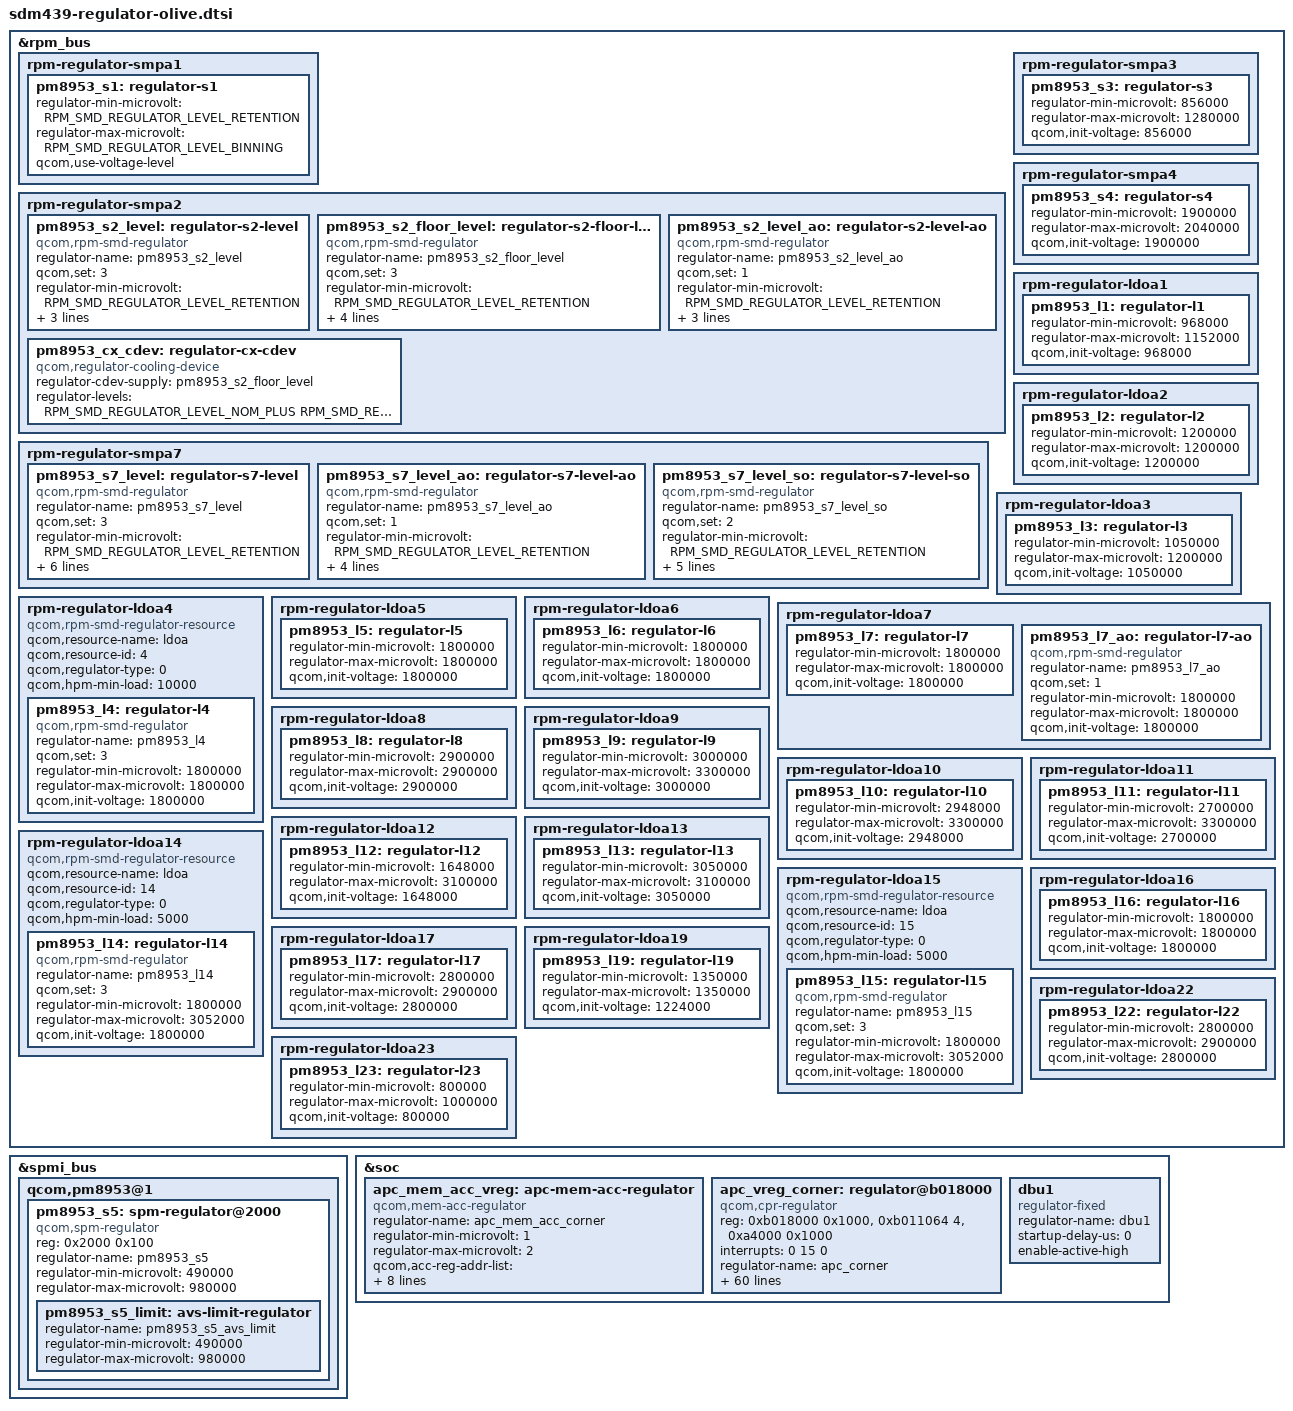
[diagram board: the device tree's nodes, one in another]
/*
 * Copyright (c) 2018-2019, The Linux Foundation. All rights reserved.
 * Copyright (C) 2021 XiaoMi, Inc.
 *
 * This program is free software; you can redistribute it and/or modify
 * it under the terms of the GNU General Public License version 2 and
 * only version 2 as published by the Free Software Foundation.
 *
 * This program is distributed in the hope that it will be useful,
 * but WITHOUT ANY WARRANTY; without even the implied warranty of
 * MERCHANTABILITY or FITNESS FOR A PARTICULAR PURPOSE.  See the
 * GNU General Public License for more details.
 */

#include <dt-bindings/interrupt-controller/arm-gic.h>

&rpm_bus {
	/* PM8953 regulators */
	rpm-regulator-smpa1 {
		status = "okay";
		pm8953_s1: regulator-s1 {
			regulator-min-microvolt =
					<RPM_SMD_REGULATOR_LEVEL_RETENTION>;
			regulator-max-microvolt =
					<RPM_SMD_REGULATOR_LEVEL_BINNING>;
			qcom,use-voltage-level;
			status = "okay";
		};
	};

	/* PM8953 S2 - VDD_CX supply */
	rpm-regulator-smpa2 {
		status = "okay";
		pm8953_s2_level: regulator-s2-level {
			compatible = "qcom,rpm-smd-regulator";
			regulator-name = "pm8953_s2_level";
			qcom,set = <3>;
			regulator-min-microvolt =
					<RPM_SMD_REGULATOR_LEVEL_RETENTION>;
			regulator-max-microvolt =
					<RPM_SMD_REGULATOR_LEVEL_BINNING>;
			qcom,use-voltage-level;
		};

		pm8953_s2_floor_level: regulator-s2-floor-level {
			compatible = "qcom,rpm-smd-regulator";
			regulator-name = "pm8953_s2_floor_level";
			qcom,set = <3>;
			regulator-min-microvolt =
					<RPM_SMD_REGULATOR_LEVEL_RETENTION>;
			regulator-max-microvolt =
					<RPM_SMD_REGULATOR_LEVEL_BINNING>;
			qcom,use-voltage-floor-level;
			qcom,always-send-voltage;
		};

		pm8953_s2_level_ao: regulator-s2-level-ao {
			compatible = "qcom,rpm-smd-regulator";
			regulator-name = "pm8953_s2_level_ao";
			qcom,set = <1>;
			regulator-min-microvolt =
					<RPM_SMD_REGULATOR_LEVEL_RETENTION>;
			regulator-max-microvolt =
					<RPM_SMD_REGULATOR_LEVEL_BINNING>;
			qcom,use-voltage-level;
		};

		pm8953_cx_cdev: regulator-cx-cdev {
			compatible = "qcom,regulator-cooling-device";
			regulator-cdev-supply = <&pm8953_s2_floor_level>;
			regulator-levels = <RPM_SMD_REGULATOR_LEVEL_NOM_PLUS
					RPM_SMD_REGULATOR_LEVEL_RETENTION>;
			#cooling-cells = <2>;
		};
	};

	rpm-regulator-smpa3 {
		status = "okay";
		pm8953_s3: regulator-s3 {
			regulator-min-microvolt = <856000>;
			regulator-max-microvolt = <1280000>;
			qcom,init-voltage = <856000>;
			status = "okay";
		};
	};

	rpm-regulator-smpa4 {
		status = "okay";
		pm8953_s4: regulator-s4 {
			regulator-min-microvolt = <1900000>;
			regulator-max-microvolt = <2040000>;
			qcom,init-voltage = <1900000>;
			status = "okay";
		};
	};

	/* VDD_MX supply */
	rpm-regulator-smpa7 {
		status = "okay";
		pm8953_s7_level: regulator-s7-level {
			compatible = "qcom,rpm-smd-regulator";
			regulator-name = "pm8953_s7_level";
			qcom,set = <3>;
			regulator-min-microvolt =
					<RPM_SMD_REGULATOR_LEVEL_RETENTION>;
			regulator-max-microvolt =
					<RPM_SMD_REGULATOR_LEVEL_BINNING>;
			qcom,init-voltage-level =
					<RPM_SMD_REGULATOR_LEVEL_RETENTION>;
			qcom,use-voltage-level;
			qcom,always-send-voltage;
		};

		pm8953_s7_level_ao: regulator-s7-level-ao {
			compatible = "qcom,rpm-smd-regulator";
			regulator-name = "pm8953_s7_level_ao";
			qcom,set = <1>;
			regulator-min-microvolt =
					<RPM_SMD_REGULATOR_LEVEL_RETENTION>;
			regulator-max-microvolt =
					<RPM_SMD_REGULATOR_LEVEL_BINNING>;
			qcom,use-voltage-level;
			qcom,always-send-voltage;
		};

		pm8953_s7_level_so: regulator-s7-level-so {
			compatible = "qcom,rpm-smd-regulator";
			regulator-name = "pm8953_s7_level_so";
			qcom,set = <2>;
			regulator-min-microvolt =
					<RPM_SMD_REGULATOR_LEVEL_RETENTION>;
			regulator-max-microvolt =
					<RPM_SMD_REGULATOR_LEVEL_BINNING>;
			qcom,init-voltage-level =
					<RPM_SMD_REGULATOR_LEVEL_RETENTION>;
			qcom,use-voltage-level;
		};
	};

	rpm-regulator-ldoa1 {
		status = "okay";
		pm8953_l1: regulator-l1 {
			regulator-min-microvolt = <968000>;
			regulator-max-microvolt = <1152000>;
			qcom,init-voltage = <968000>;
			status = "okay";
		};
	};

	rpm-regulator-ldoa2 {
		status = "okay";
		pm8953_l2: regulator-l2 {
			regulator-min-microvolt = <1200000>;
			regulator-max-microvolt = <1200000>;
			qcom,init-voltage = <1200000>;
			status = "okay";
		};
	};

	rpm-regulator-ldoa3 {
		status = "okay";
		pm8953_l3: regulator-l3 {
			regulator-min-microvolt = <1050000>;
			regulator-max-microvolt = <1200000>;
			qcom,init-voltage = <1050000>;
			status = "okay";
		};
	};

	rpm-regulator-ldoa4 {
		compatible = "qcom,rpm-smd-regulator-resource";
		qcom,resource-name = "ldoa";
		qcom,resource-id = <4>;
		qcom,regulator-type = <0>;
		qcom,hpm-min-load = <10000>;
		status = "okay";
		pm8953_l4: regulator-l4 {
			compatible = "qcom,rpm-smd-regulator";
			regulator-name = "pm8953_l4";
			qcom,set = <3>;
			regulator-min-microvolt = <1800000>;
			regulator-max-microvolt = <1800000>;
			qcom,init-voltage = <1800000>;
			status = "okay";
		};
	};

	rpm-regulator-ldoa5 {
		status = "okay";
		pm8953_l5: regulator-l5 {
			regulator-min-microvolt = <1800000>;
			regulator-max-microvolt = <1800000>;
			qcom,init-voltage = <1800000>;
			status = "okay";
		};
	};

	rpm-regulator-ldoa6 {
		status = "okay";
		pm8953_l6: regulator-l6 {
			regulator-min-microvolt = <1800000>;
			regulator-max-microvolt = <1800000>;
			qcom,init-voltage = <1800000>;
			status = "okay";
		};
	};

	rpm-regulator-ldoa7 {
		status = "okay";
		pm8953_l7: regulator-l7 {
			regulator-min-microvolt = <1800000>;
			regulator-max-microvolt = <1800000>;
			qcom,init-voltage = <1800000>;
			status = "okay";
		};

		pm8953_l7_ao: regulator-l7-ao {
			compatible = "qcom,rpm-smd-regulator";
			regulator-name = "pm8953_l7_ao";
			qcom,set = <1>;
			regulator-min-microvolt = <1800000>;
			regulator-max-microvolt = <1800000>;
			qcom,init-voltage = <1800000>;
		};
	};

	rpm-regulator-ldoa8 {
		status = "okay";
		pm8953_l8: regulator-l8 {
			regulator-min-microvolt = <2900000>;
			regulator-max-microvolt = <2900000>;
			qcom,init-voltage = <2900000>;
			status = "okay";
		};
	};

	rpm-regulator-ldoa9 {
		status = "okay";
		pm8953_l9: regulator-l9 {
			regulator-min-microvolt = <3000000>;
			regulator-max-microvolt = <3300000>;
			qcom,init-voltage = <3000000>;
			status = "okay";
		};
	};

	rpm-regulator-ldoa10 {
		status = "okay";
		pm8953_l10: regulator-l10 {
			regulator-min-microvolt = <2948000>;
			regulator-max-microvolt = <3300000>;
			qcom,init-voltage = <2948000>;
			status = "okay";
		};
	};

	rpm-regulator-ldoa11 {
		status = "okay";
		pm8953_l11: regulator-l11 {
			regulator-min-microvolt = <2700000>;
			regulator-max-microvolt = <3300000>;
			qcom,init-voltage = <2700000>;
			status = "okay";
		};
	};

	rpm-regulator-ldoa12 {
		status = "okay";
		pm8953_l12: regulator-l12 {
			regulator-min-microvolt = <1648000>;
			regulator-max-microvolt = <3100000>;
			qcom,init-voltage = <1648000>;
			status = "okay";
		};
	};

	rpm-regulator-ldoa13 {
		status = "okay";
		pm8953_l13: regulator-l13 {
			regulator-min-microvolt = <3050000>;
			regulator-max-microvolt = <3100000>;
			qcom,init-voltage = <3050000>;
			status = "okay";
		};
	};

	rpm-regulator-ldoa14 {
		compatible = "qcom,rpm-smd-regulator-resource";
		qcom,resource-name = "ldoa";
		qcom,resource-id = <14>;
		qcom,regulator-type = <0>;
		qcom,hpm-min-load = <5000>;
		status = "okay";
		pm8953_l14: regulator-l14 {
			compatible = "qcom,rpm-smd-regulator";
			regulator-name = "pm8953_l14";
			qcom,set = <3>;
			regulator-min-microvolt = <1800000>;
			regulator-max-microvolt = <3052000>;
			qcom,init-voltage = <1800000>;
			status = "okay";
		};
	};

	rpm-regulator-ldoa15 {
		compatible = "qcom,rpm-smd-regulator-resource";
		qcom,resource-name = "ldoa";
		qcom,resource-id = <15>;
		qcom,regulator-type = <0>;
		qcom,hpm-min-load = <5000>;
		status = "okay";
		pm8953_l15: regulator-l15 {
			compatible = "qcom,rpm-smd-regulator";
			regulator-name = "pm8953_l15";
			qcom,set = <3>;
			regulator-min-microvolt = <1800000>;
			regulator-max-microvolt = <3052000>;
			qcom,init-voltage = <1800000>;
			status = "okay";
		};
	};

	rpm-regulator-ldoa16 {
		status = "okay";
		pm8953_l16: regulator-l16 {
			regulator-min-microvolt = <1800000>;
			regulator-max-microvolt = <1800000>;
			qcom,init-voltage = <1800000>;
			status = "okay";
		};
	};

	rpm-regulator-ldoa17 {
		status = "okay";
		pm8953_l17: regulator-l17 {
			regulator-min-microvolt = <2800000>;
			regulator-max-microvolt = <2900000>;
			qcom,init-voltage = <2800000>;
			status = "okay";
		};
	};

	rpm-regulator-ldoa19 {
		status = "okay";
		pm8953_l19: regulator-l19 {
			regulator-min-microvolt = <1350000>;
			regulator-max-microvolt = <1350000>;
			qcom,init-voltage = <1224000>;
			status = "okay";
		};
	};

	rpm-regulator-ldoa22 {
		status = "okay";
		pm8953_l22: regulator-l22 {
			regulator-min-microvolt = <2800000>;
			regulator-max-microvolt = <2900000>;
			qcom,init-voltage = <2800000>;
			status = "okay";
		};
	};

	rpm-regulator-ldoa23 {
		status = "okay";
		pm8953_l23: regulator-l23 {
			regulator-min-microvolt = <800000>;
			regulator-max-microvolt = <1000000>;
			qcom,init-voltage = <800000>;
			status = "okay";
		};
	};
};

&spmi_bus {
	qcom,pm8953@1 {
		/* PM8953 S5 + S6 = VDD_APC_supply */
		pm8953_s5: spm-regulator@2000 {
			compatible = "qcom,spm-regulator";
			reg = <0x2000 0x100>;
			regulator-name = "pm8953_s5";
			regulator-min-microvolt = <490000>;
			regulator-max-microvolt = <980000>;

			pm8953_s5_limit: avs-limit-regulator {
				regulator-name = "pm8953_s5_avs_limit";
				regulator-min-microvolt = <490000>;
				regulator-max-microvolt = <980000>;
			};
		};
	};
};

&soc {
	apc_mem_acc_vreg: apc-mem-acc-regulator {
		compatible = "qcom,mem-acc-regulator";
		regulator-name = "apc_mem_acc_corner";
		regulator-min-microvolt = <1>;
		regulator-max-microvolt = <2>;
		qcom,acc-reg-addr-list = <0x01942138 0x01942130 0x01946004>;
		qcom,acc-init-reg-config = <1 0xff>;
		qcom,num-acc-corners = <2>;
		qcom,boot-acc-corner = <1>;
		qcom,corner1-reg-config =
			/* 1 -> 1 */
			<(-1) (-1)>, <(-1) (-1)>,
			/* 1 -> 2 */
			<  2 0xffff>, < 3  0xff>;
		qcom,corner2-reg-config =
			/* 2 -> 1 */
			<  2 0x5555>, < 3  0x55>,
			/* 2 -> 2 */
			<(-1) (-1)>, <(-1) (-1)>;
	};

	apc_vreg_corner: regulator@b018000 {
		compatible = "qcom,cpr-regulator";
		reg = <0xb018000 0x1000>, <0xb011064 4>, <0xa4000 0x1000>;
		reg-names = "rbcpr", "rbcpr_clk", "efuse_addr";
		interrupts = <0 15 0>;
		regulator-name = "apc_corner";
		regulator-min-microvolt = <1>;
		regulator-max-microvolt = <6>;

		qcom,cpr-fuse-corners = <3>;
		qcom,cpr-voltage-ceiling = <810000 845000 980000>;
		qcom,cpr-voltage-floor =   <700000 700000 790000>;
		vdd-apc-supply = <&pm8953_s5>;
		mem-acc-supply = <&apc_mem_acc_vreg>;
		qcom,mem-acc-corner-map = <1 1 1 1 2 2>;

		qcom,cpr-ref-clk = <19200>;
		qcom,cpr-timer-delay = <5000>;
		qcom,cpr-timer-cons-up = <0>;
		qcom,cpr-timer-cons-down = <2>;
		qcom,cpr-irq-line = <0>;
		qcom,cpr-step-quotient = <10>;
		qcom,cpr-up-threshold = <2>;
		qcom,cpr-down-threshold = <4>;
		qcom,cpr-idle-clocks = <15>;
		qcom,cpr-gcnt-time = <1>;
		qcom,vdd-apc-step-up-limit = <1>;
		qcom,vdd-apc-step-down-limit = <1>;
		qcom,cpr-apc-volt-step = <5000>;

		qcom,cpr-fuse-row = <67 0>;
		qcom,cpr-fuse-target-quot = <42 24 6>;
		qcom,cpr-fuse-ro-sel = <60 57 54>;
		qcom,cpr-init-voltage-ref = <760000 795000 910000>;
		qcom,cpr-fuse-init-voltage =
					<67 36 6 0>,
					<67 18 6 0>,
					<67  0 6 0>;
		qcom,cpr-fuse-quot-offset =
					<71 26 6 0>,
					<71 20 6 0>,
					<70 54 7 0>;
		qcom,cpr-fuse-quot-offset-scale = <5 5 5>;
		qcom,cpr-init-voltage-step = <10000>;
		qcom,cpr-corner-map = <1 2 3 3 3 3>;
		qcom,cpr-corner-frequency-map =
				<1 1305600000>,
				<2 1497600000>,
				<3 1708800000>,
				<4 1804800000>,
				<5 1958400000>,
				<6 2016000000>;
		qcom,speed-bin-fuse-sel = <37 34 3 0>;
		qcom,cpr-speed-bin-max-corners =
					<0 (-1) 1 2 5>,
					<1 (-1) 1 2 5>,
					<4 (-1) 1 2 6>,
					<5 (-1) 1 2 6>;
		qcom,cpr-fuse-revision = <69 39 3 0>;
		qcom,cpr-quot-adjust-scaling-factor-max = <0 1400 1400>;
		qcom,cpr-voltage-scaling-factor-max = <0 2000 2000>;
		qcom,cpr-scaled-init-voltage-as-ceiling;

		qcom,cpr-fuse-version-map =
			/* <Speed-bin pvs-version cpr-rev ... ... ...> */
			<(-1)    (-1)   ( 0)   (-1)    (-1)    (-1)>,
			<(-1)    (-1)   ( 1)   (-1)    (-1)    (-1)>,
			<(-1)    (-1)   (-1)   (-1)    (-1)    (-1)>;

		qcom,cpr-quotient-adjustment =
			<66      77      66>, /* SVSP/NOM/TUR:30/35/30 mV */
			<(-74)    0   (-30)>, /* SVSP/NOM/TUR:-34/0/-14 mV */
			<0        0       0>;

		qcom,cpr-floor-to-ceiling-max-range =
			<50000 50000 65000 65000 65000 65000>,
			<50000 50000 65000 65000 65000 65000>,
			<50000 50000 65000 65000 65000 65000>;

		qcom,cpr-voltage-ceiling-override =
			<(-1) (-1) 810000 845000 885000 980000 980000 980000>;

		qcom,cpr-virtual-corner-quotient-adjustment =
			<0  0    0   0   0    0>,
			<0  0  (-22) 0   0    0>, /* NOMP: -10 mV */
			<0  0    0   0   0    0>;

		qcom,cpr-enable;
	};

	dbu1: dbu1 {
		compatible = "regulator-fixed";
		regulator-name = "dbu1";
		startup-delay-us = <0>;
		enable-active-high;
	};
};
